# RK3399-AP register map
File version: 1
CPU: CA7 r0p1, little endian, MPU, FPU, I-cache, D-cache, VTOR, 4 interrupt priority bits, 0 interrupts
Registers are 32-bit, read-write, reset 0x0 unless marked. A register's access mark holds for its fields unless they carry their own. Offsets are from the block's base; [hi:lo] are bit positions; {n}, {i} and the like mark numbered series; 'fields as' and 'values as' point back to an identical list.

## EFUSE0
Base 0xFF690000
Same registers: EFUSE1 0xFFFA0000
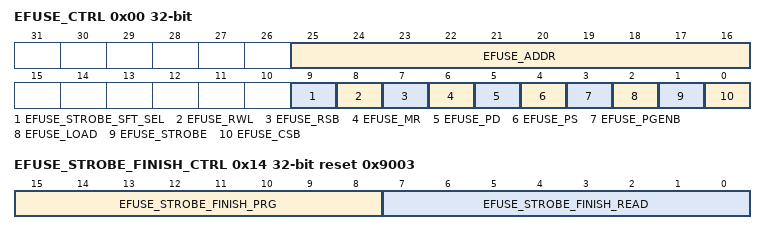
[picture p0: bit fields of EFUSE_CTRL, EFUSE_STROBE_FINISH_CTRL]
0x00 EFUSE_CTRL — efuse control register/eFuse control register
  [25:16] EFUSE_ADDR — efuse address pins :A[9:0]
  [9] EFUSE_STROBE_SFT_SEL — efuse strobe control software mode select, active high
  [8] EFUSE_RWL — efuse redundancy information row select (active high) : RWL
  [7] EFUSE_RSB — efuse redundancy enable(active low) : RSB
  [6] EFUSE_MR — efuse read trip point setting, MR = L for normal read mode; MR = H for margin read1 mode : MR
  [5] EFUSE_PD — efuse power down enable (active high) : PD
  [4] EFUSE_PS — efuse pass 1.8V program voltage to internal for program(active high) : PS
  [3] EFUSE_PGENB — efuse program enable (active low) : PGENB
  [2] EFUSE_LOAD — efuse turn on sense amplifier and load data into latch (active high) : LOAD
  [1] EFUSE_STROBE — efuse turn on the array for read or program access (active high) : STROBE
  [0] EFUSE_CSB — efuse chip select enable signal, active low : CSB
0x04 EFUSE_DOUT ro — efuse data out register/eFuse data out register
  [31:0] EFUSE_DOUT — eFuse data output
0x08 EFUSE_RF ro — efuse redundancy bit used indicator register
  [3:0] EFUSE_RF_R — efuse redundancy bit used indicator register for RF3~RF0, Output high once the redundancy bit has been used.
0x10 EFUSE_JTAG_PASSWD reset 0xCF7680A — Jtag password/eFuse jtag passwd register
  [31:0] JTAG_PASSWD — Jtag password for jtag monitor
0x14 EFUSE_STROBE_FINISH_CTRL reset 0x9003 — efuse strobe finish control register/eFuse jtag passwd register
  [15:8] EFUSE_STROBE_FINISH_PRG — efuse read strobe finish control in hardware mode.
  [7:0] EFUSE_STROBE_FINISH_READ — efuse program strobe finish control in hardware mode.

## MAILBOX1
Base 0xFF390000
Same registers: MAILBOX0 0xFF6B0000
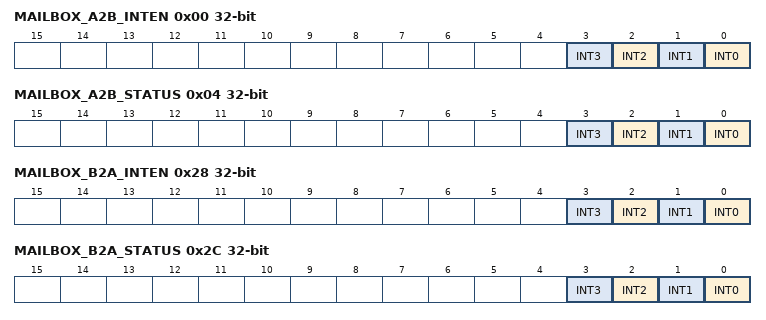
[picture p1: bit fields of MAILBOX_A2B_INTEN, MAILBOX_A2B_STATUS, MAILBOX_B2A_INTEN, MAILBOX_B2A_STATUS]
0x00 MAILBOX_A2B_INTEN — Cortex-A53/Cortex-A72 to Cortex-M0 interrupt enable register/Cortex-A53/Cortex-A72 to MCU interrupt enable register
  [n] INT{n} (n=0..3) — interrupt enable for int{n}
0x04 MAILBOX_A2B_STATUS — Cortex-A53/Cortex-A72 to Cortex-M0 interrupt status register/Cortex-A53/Cortex-A72 to MCU interrupt status register
  [n] INT{n} (n=0..3) — interrupt status for int{n}. when writte 1, int is cleared.
{0x8+8i} MAILBOX_A2B_CMD_{i} (i=0..3) — Cortex-A53/Cortex-A72 to Cortex-M0 command {i}/Cortex-A53/Cortex-A72 to MCU command {i}
  [31:0] COMMAND — command of Cortex-A53/Cortex-A72 to Cortex-M0
{0xC+8i} MAILBOX_A2B_DAT_{i} (i=0..3) — Cortex-A53/Cortex-A72 to Cortex-M0 data {i}/Cortex-A53/Cortex-A72 to MCU data {i}
  [31:0] DATA — data of Cortex-A53/Cortex-A72 to Cortex-M0
0x28 MAILBOX_B2A_INTEN — Cortex-A53/Cortex-A72 to Cortex-M0 interrupt enable register/Cortex-A53/Cortex-A72 to MCU interrupt enable register
  [n] INT{n} (n=0..3) — interrupt enable for int{n}
0x2C MAILBOX_B2A_STATUS — Cortex-M0 to Cortex-A53/Cortex-A72 interrupt status register/MCU to Cortex-A53/Cortex-A72 interrupt status register
  fields as MAILBOX_A2B_STATUS
0x30 MAILBOX_B2A_CMD_0 — Cortex-M0 to Cortex-A53/Cortex-A72 command 0/MCU to Cortex-A53/Cortex-A72 command 0
  [31:0] COMMAND — command of MCU to Cortex-A53/Cortex-A72
0x34 MAILBOX_B2A_DAT_0 — Cortex-M0 to Cortex-A53/Cortex-A72 data 0/MCU to Cortex-A53/Cortex-A72 data 0
  [31:0] DATA — data of MCU to Cortex-A53/Cortex-A72
0x38 MAILBOX_B2A_CMD_1 — Cortex-M0 to Cortex-A53/Cortex-A72 command 1/MCU to Cortex-A53/Cortex-A72 command 1
  [31:0] COMMAND — command of MCU to Cortex-A53/Cortex-A72
0x3C MAILBOX_B2A_DAT_1 — Cortex-M0 to Cortex-A53/Cortex-A72 data 1/MCU to Cortex-A53/Cortex-A72 data 1
  [31:0] DATA — data of MCU to Cortex-A53/Cortex-A72
0x40 MAILBOX_B2A_CMD_2 — Cortex-M0 to Cortex-A53/Cortex-A72 command 2/MCU to Cortex-A53/Cortex-A72 command 2
  [31:0] COMMAND — command of Cortex-M0 to Cortex-A53/Cortex-A72
0x44 MAILBOX_B2A_DAT_2 — Cortex-M0 to Cortex-A53/Cortex-A72 data 2/MCU to Cortex-A53/Cortex-A72 data 2
  [31:0] DATA — data of Cortex-M0 to Cortex-A53/Cortex-A72
0x48 MAILBOX_B2A_CMD_3 — Cortex-M0 to Cortex-A53/Cortex-A72 command 3/MCU to Cortex-A53/Cortex-A72 command 3
  [31:0] COMMAND — command of Cortex-M0 to Cortex-A53/Cortex-A72
0x4C MAILBOX_B2A_DAT_3 — Cortex-M0 to Cortex-A53/Cortex-A72 data 3/MCU to Cortex-A53/Cortex-A72 data 3
  [31:0] DATA — data of Cortex-M0 to Cortex-A53/Cortex-A72
{0x100+4i} MAILBOX_ATOMIC_LOCK_{i:02} (i=0..31) — Lock flag register {i:02}
  [0] ATOMIC_LOCK_{i:02} — lock flag bit {i:02}
